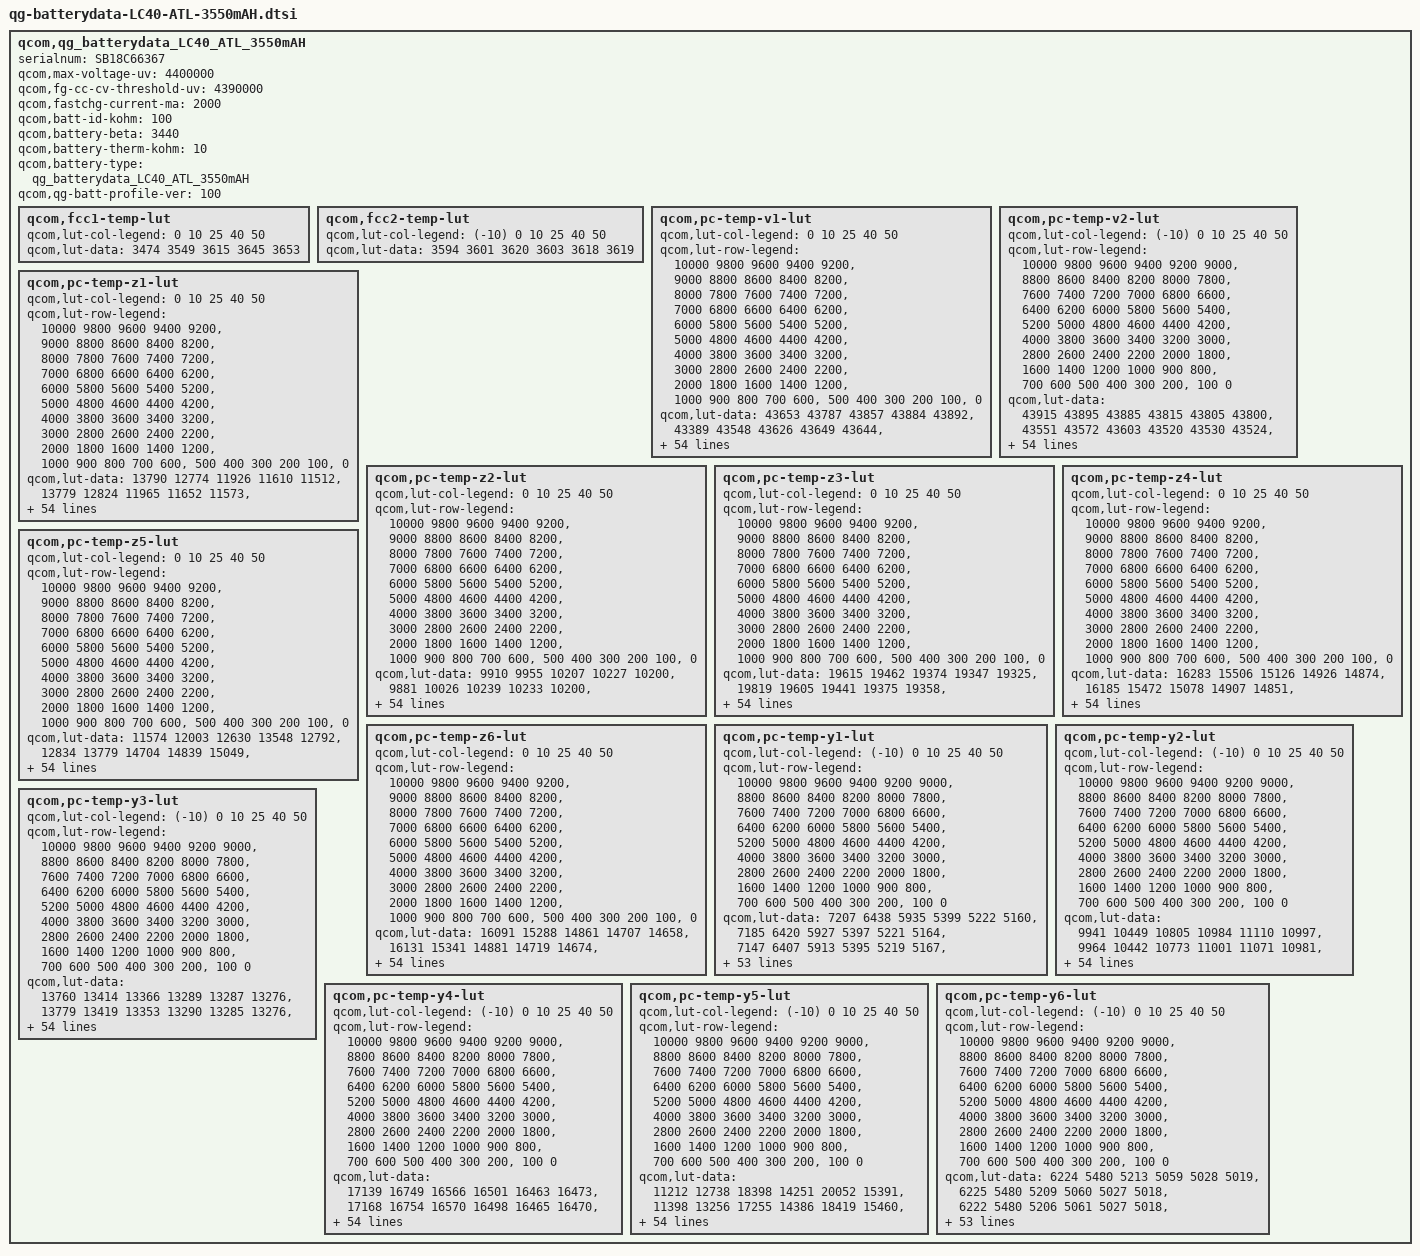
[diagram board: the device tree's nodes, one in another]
/* Copyright (c) 2014-2015, The Linux Foundation. All rights reserved.
 *
 * This program is free software; you can redistribute it and/or modify
 * it under the terms of the GNU General Public License version 2 and
 * only version 2 as published by the Free Software Foundation.
 *
 * This program is distributed in the hope that it will be useful,
 * but WITHOUT ANY WARRANTY; without even the implied warranty of
 * MERCHANTABILITY or FITNESS FOR A PARTICULAR PURPOSE.  See the
 * GNU General Public License for more details.
 */

qcom,qg_batterydata_LC40_ATL_3550mAH {
	/* qg_batterydata_LC40_ATL_3550mAH */
        serialnum = "SB18C66367";
   	qcom,max-voltage-uv = <4400000>;
    	qcom,fg-cc-cv-threshold-uv = <4390000>;
    	qcom,fastchg-current-ma = <2000>;
   	qcom,batt-id-kohm = <100>;
   	qcom,battery-beta = <3440>;
   	qcom,battery-therm-kohm = <10>;
   	qcom,battery-type = "qg_batterydata_LC40_ATL_3550mAH";
   	qcom,qg-batt-profile-ver = <100>;

	qcom,fcc1-temp-lut {
		qcom,lut-col-legend = <0 10 25 40 50>;
		qcom,lut-data = <3474 3549 3615 3645 3653>;
	};

	qcom,fcc2-temp-lut {
		qcom,lut-col-legend = <(-10) 0 10 25 40 50>;
		qcom,lut-data = <3594 3601 3620 3603 3618 3619>;
	};

	qcom,pc-temp-v1-lut {
		qcom,lut-col-legend = <0 10 25 40 50>;
		qcom,lut-row-legend = <10000 9800 9600 9400 9200>,
			<9000 8800 8600 8400 8200>,
			<8000 7800 7600 7400 7200>,
			<7000 6800 6600 6400 6200>,
			<6000 5800 5600 5400 5200>,
			<5000 4800 4600 4400 4200>,
			<4000 3800 3600 3400 3200>,
			<3000 2800 2600 2400 2200>,
			<2000 1800 1600 1400 1200>,
			<1000 900 800 700 600>,
			<500 400 300 200 100>,
			<0>;
		qcom,lut-data = <43653 43787 43857 43884 43892>,
			<43389 43548 43626 43649 43644>,
			<43118 43298 43383 43417 43420>,
			<42874 43047 43143 43187 43190>,
			<42643 42804 42903 42951 42961>,
			<42407 42563 42660 42714 42723>,
			<42171 42327 42419 42476 42488>,
			<41942 42092 42182 42238 42252>,
			<41717 41863 41949 42000 42016>,
			<41501 41636 41718 41767 41783>,
			<41303 41417 41490 41539 41555>,
			<41115 41216 41272 41317 41332>,
			<40908 41019 41069 41101 41111>,
			<40675 40808 40868 40892 40895>,
			<40445 40583 40650 40682 40687>,
			<40218 40368 40431 40475 40487>,
			<40006 40159 40229 40278 40295>,
			<39842 39972 40039 40093 40112>,
			<39708 39821 39870 39918 39936>,
			<39579 39687 39731 39767 39778>,
			<39451 39549 39586 39612 39618>,
			<39327 39410 39415 39393 39410>,
			<39200 39242 39228 39130 39161>,
			<39075 38991 39005 38940 38968>,
			<38953 38754 38759 38801 38822>,
			<38835 38610 38616 38682 38695>,
			<38716 38501 38540 38578 38580>,
			<38586 38425 38471 38483 38476>,
			<38463 38370 38395 38390 38382>,
			<38376 38322 38321 38303 38295>,
			<38310 38276 38254 38227 38216>,
			<38260 38234 38190 38157 38143>,
			<38221 38193 38137 38098 38079>,
			<38188 38154 38090 38046 38025>,
			<38160 38121 38049 37997 37972>,
			<38134 38091 38014 37948 37915>,
			<38104 38057 37977 37899 37855>,
			<38069 38017 37935 37849 37792>,
			<38025 37967 37886 37796 37724>,
			<37957 37894 37817 37726 37644>,
			<37865 37789 37712 37622 37548>,
			<37756 37674 37594 37505 37437>,
			<37621 37540 37459 37371 37300>,
			<37468 37391 37310 37225 37153>,
			<37321 37244 37163 37078 37011>,
			<37222 37154 37075 36993 36932>,
			<37192 37129 37050 36968 36910>,
			<37172 37107 37035 36952 36892>,
			<37150 37088 37017 36934 36873>,
			<37109 37050 36976 36882 36813>,
			<36909 36853 36770 36652 36557>,
			<36490 36430 36341 36209 36110>,
			<35919 35861 35774 35638 35537>,
			<35141 35084 35000 34857 34753>,
			<33932 33882 33805 33656 33550>,
			<30000 30000 30000 30000 30000>;
	};

	qcom,pc-temp-v2-lut {
		qcom,lut-col-legend = <(-10) 0 10 25 40 50>;
		qcom,lut-row-legend = <10000 9800 9600 9400 9200 9000>,
			<8800 8600 8400 8200 8000 7800>,
			<7600 7400 7200 7000 6800 6600>,
			<6400 6200 6000 5800 5600 5400>,
			<5200 5000 4800 4600 4400 4200>,
			<4000 3800 3600 3400 3200 3000>,
			<2800 2600 2400 2200 2000 1800>,
			<1600 1400 1200 1000 900 800>,
			<700 600 500 400 300 200>,
			<100 0>;
		qcom,lut-data = <43915 43895 43885 43815 43805 43800>,
			<43551 43572 43603 43520 43530 43524>,
			<43220 43274 43333 43244 43267 43262>,
			<42928 43002 43073 42988 43017 43014>,
			<42666 42754 42824 42749 42778 42779>,
			<42408 42508 42581 42511 42540 42543>,
			<42151 42263 42344 42273 42303 42306>,
			<41912 42025 42110 42037 42067 42070>,
			<41703 41796 41878 41805 41834 41837>,
			<41501 41573 41648 41576 41604 41606>,
			<41268 41355 41421 41350 41377 41381>,
			<41018 41143 41199 41129 41154 41161>,
			<40814 40942 40993 40919 40939 40944>,
			<40666 40760 40808 40723 40735 40734>,
			<40478 40546 40605 40523 40531 40528>,
			<40085 40234 40360 40303 40320 40325>,
			<39665 39906 40107 40089 40119 40131>,
			<39463 39665 39873 39915 39944 39954>,
			<39330 39464 39649 39759 39781 39786>,
			<39183 39289 39443 39583 39618 39622>,
			<39020 39137 39252 39386 39457 39463>,
			<38868 38991 39074 39183 39270 39278>,
			<38743 38843 38907 38966 39019 39029>,
			<38617 38701 38756 38767 38789 38800>,
			<38457 38568 38623 38620 38639 38649>,
			<38283 38445 38503 38498 38520 38527>,
			<38169 38335 38393 38391 38410 38416>,
			<38094 38236 38292 38294 38312 38316>,
			<38031 38140 38201 38206 38222 38224>,
			<37973 38037 38119 38124 38140 38138>,
			<37920 37951 38042 38050 38067 38062>,
			<37870 37897 37962 37982 37999 37993>,
			<37823 37856 37889 37921 37937 37930>,
			<37773 37818 37832 37863 37875 37869>,
			<37723 37783 37785 37809 37815 37810>,
			<37670 37746 37743 37756 37742 37731>,
			<37613 37707 37707 37702 37650 37616>,
			<37554 37664 37668 37644 37559 37505>,
			<37490 37614 37624 37575 37478 37416>,
			<37425 37557 37565 37500 37401 37335>,
			<37359 37485 37475 37423 37328 37262>,
			<37292 37390 37380 37333 37240 37175>,
			<37223 37275 37262 37210 37124 37058>,
			<37131 37136 37131 37086 37000 36933>,
			<37039 37006 36988 36940 36860 36802>,
			<36944 36916 36928 36897 36831 36772>,
			<36898 36885 36906 36884 36821 36761>,
			<36847 36848 36884 36872 36803 36748>,
			<36782 36792 36850 36845 36780 36721>,
			<36684 36706 36786 36781 36700 36624>,
			<36480 36508 36562 36544 36393 36291>,
			<36106 36096 36091 36068 35905 35797>,
			<35524 35486 35450 35451 35260 35147>,
			<34665 34639 34563 34627 34388 34262>,
			<33284 33307 33324 33395 33063 32929>,
			<28120 27938 28185 28434 27961 27898>;
	};

	qcom,pc-temp-z1-lut {
		qcom,lut-col-legend = <0 10 25 40 50>;
		qcom,lut-row-legend = <10000 9800 9600 9400 9200>,
			<9000 8800 8600 8400 8200>,
			<8000 7800 7600 7400 7200>,
			<7000 6800 6600 6400 6200>,
			<6000 5800 5600 5400 5200>,
			<5000 4800 4600 4400 4200>,
			<4000 3800 3600 3400 3200>,
			<3000 2800 2600 2400 2200>,
			<2000 1800 1600 1400 1200>,
			<1000 900 800 700 600>,
			<500 400 300 200 100>,
			<0>;
		qcom,lut-data = <13790 12774 11926 11610 11512>,
			<13779 12824 11965 11652 11573>,
			<13807 12796 11963 11657 11574>,
			<13790 12771 11956 11655 11576>,
			<13752 12753 11942 11651 11575>,
			<13735 12742 11933 11648 11574>,
			<13726 12723 11928 11647 11577>,
			<13719 12702 11926 11647 11578>,
			<13711 12688 11924 11647 11578>,
			<13702 12679 11924 11647 11578>,
			<13685 12674 11923 11648 11579>,
			<13657 12682 11923 11648 11579>,
			<13624 12693 11925 11649 11579>,
			<13572 12686 11926 11650 11580>,
			<13543 12657 11924 11650 11581>,
			<13554 12642 11921 11650 11581>,
			<13575 12638 11921 11650 11582>,
			<13586 12636 11922 11651 11585>,
			<13595 12648 11924 11652 11587>,
			<13598 12669 11927 11655 11588>,
			<13601 12676 11931 11657 11589>,
			<13606 12678 11936 11659 11589>,
			<13615 12680 11941 11661 11591>,
			<13627 12687 11946 11663 11593>,
			<13642 12696 11951 11666 11596>,
			<13662 12704 11956 11669 11600>,
			<13674 12713 11960 11673 11604>,
			<13661 12717 11965 11677 11608>,
			<13641 12721 11972 11681 11612>,
			<13640 12725 11979 11685 11615>,
			<13651 12735 11984 11689 11617>,
			<13662 12745 11988 11692 11620>,
			<13672 12750 11994 11695 11623>,
			<13682 12753 12001 11699 11627>,
			<13693 12759 12008 11703 11630>,
			<13704 12774 12015 11706 11632>,
			<13712 12787 12021 11708 11634>,
			<13718 12799 12027 11711 11636>,
			<13721 12811 12032 11714 11637>,
			<13725 12821 12039 11718 11640>,
			<13733 12833 12046 11721 11643>,
			<13753 12840 12052 11724 11645>,
			<13797 12845 12060 11728 11647>,
			<13802 12860 12064 11730 11649>,
			<13791 12880 12067 11732 11651>,
			<13785 12863 12078 11734 11653>,
			<13808 12861 12075 11734 11653>,
			<13783 12865 12078 11736 11653>,
			<13768 12873 12081 11736 11654>,
			<13771 12872 12083 11741 11657>,
			<13802 12893 12089 11745 11662>,
			<13841 12911 12100 11754 11669>,
			<13852 12943 12123 11766 11681>,
			<13889 12986 12154 11784 11696>,
			<13889 12986 12154 11784 11696>,
			<13889 12986 12154 11784 11696>;
	};

	qcom,pc-temp-z2-lut {
		qcom,lut-col-legend = <0 10 25 40 50>;
		qcom,lut-row-legend = <10000 9800 9600 9400 9200>,
			<9000 8800 8600 8400 8200>,
			<8000 7800 7600 7400 7200>,
			<7000 6800 6600 6400 6200>,
			<6000 5800 5600 5400 5200>,
			<5000 4800 4600 4400 4200>,
			<4000 3800 3600 3400 3200>,
			<3000 2800 2600 2400 2200>,
			<2000 1800 1600 1400 1200>,
			<1000 900 800 700 600>,
			<500 400 300 200 100>,
			<0>;
		qcom,lut-data = <9910 9955 10207 10227 10200>,
			<9881 10026 10239 10233 10200>,
			<9946 10052 10288 10250 10179>,
			<10003 10010 10275 10181 10147>,
			<10039 9981 10249 10307 10219>,
			<10038 9965 10214 10299 10304>,
			<10023 9962 10196 10248 10247>,
			<10018 9962 10191 10246 10234>,
			<10021 9962 10192 10283 10262>,
			<10026 9963 10197 10300 10278>,
			<10030 9964 10211 10294 10209>,
			<10033 9969 10224 10283 10129>,
			<10031 9977 10237 10245 10118>,
			<10012 9984 10245 10190 10115>,
			<9993 9990 10229 10169 10120>,
			<9986 9999 10202 10147 10133>,
			<9980 10017 10204 10141 10146>,
			<9973 10040 10228 10137 10156>,
			<9965 10075 10253 10136 10168>,
			<9957 10114 10276 10163 10188>,
			<9947 10133 10302 10221 10223>,
			<9938 10145 10341 10364 10334>,
			<9929 10152 10375 10592 10551>,
			<9921 10156 10364 10599 10587>,
			<9921 10160 10320 10352 10430>,
			<9928 10161 10295 10229 10342>,
			<9936 10162 10268 10287 10405>,
			<9947 10161 10256 10344 10472>,
			<9959 10157 10311 10350 10394>,
			<9965 10156 10375 10352 10219>,
			<9969 10158 10373 10332 10136>,
			<9973 10162 10361 10267 10088>,
			<9978 10168 10358 10243 10075>,
			<9984 10178 10359 10249 10092>,
			<9988 10184 10360 10257 10121>,
			<9994 10190 10365 10278 10175>,
			<10001 10197 10375 10317 10248>,
			<10014 10205 10395 10364 10311>,
			<10027 10215 10427 10420 10368>,
			<10037 10227 10455 10453 10383>,
			<10047 10240 10485 10508 10382>,
			<10061 10245 10495 10527 10381>,
			<10080 10244 10493 10464 10383>,
			<10103 10249 10492 10430 10377>,
			<10177 10283 10499 10453 10355>,
			<10409 10446 10532 10403 10335>,
			<10481 10484 10524 10395 10337>,
			<10431 10497 10499 10394 10336>,
			<10411 10571 10497 10428 10376>,
			<10418 10628 10540 10487 10433>,
			<10472 10587 10624 10413 10271>,
			<10319 10549 10586 10263 10109>,
			<10145 10508 10524 10199 10054>,
			<9956 10341 10465 10125 9980>,
			<9956 10341 10465 10125 9980>,
			<9956 10341 10465 10125 9980>;
	};

	qcom,pc-temp-z3-lut {
		qcom,lut-col-legend = <0 10 25 40 50>;
		qcom,lut-row-legend = <10000 9800 9600 9400 9200>,
			<9000 8800 8600 8400 8200>,
			<8000 7800 7600 7400 7200>,
			<7000 6800 6600 6400 6200>,
			<6000 5800 5600 5400 5200>,
			<5000 4800 4600 4400 4200>,
			<4000 3800 3600 3400 3200>,
			<3000 2800 2600 2400 2200>,
			<2000 1800 1600 1400 1200>,
			<1000 900 800 700 600>,
			<500 400 300 200 100>,
			<0>;
		qcom,lut-data = <19615 19462 19374 19347 19325>,
			<19819 19605 19441 19375 19358>,
			<19970 19632 19460 19388 19361>,
			<19893 19737 19455 19386 19374>,
			<19775 19743 19524 19418 19384>,
			<19734 19744 19526 19445 19427>,
			<19707 19742 19527 19444 19428>,
			<19698 19734 19517 19443 19428>,
			<19702 19726 19497 19437 19423>,
			<19706 19713 19486 19430 19416>,
			<19710 19697 19480 19419 19404>,
			<19715 19675 19472 19408 19393>,
			<19725 19650 19458 19402 19389>,
			<19744 19633 19449 19397 19386>,
			<19759 19621 19453 19392 19382>,
			<19761 19607 19458 19386 19375>,
			<19759 19591 19457 19381 19370>,
			<19760 19575 19447 19377 19366>,
			<19761 19556 19439 19373 19362>,
			<19762 19540 19431 19366 19356>,
			<19764 19539 19427 19361 19350>,
			<19765 19548 19436 19370 19355>,
			<19774 19561 19448 19395 19370>,
			<19786 19591 19449 19395 19370>,
			<19790 19615 19446 19359 19338>,
			<19797 19614 19439 19341 19321>,
			<19807 19611 19422 19348 19363>,
			<19819 19607 19412 19360 19407>,
			<19831 19601 19416 19383 19407>,
			<19831 19595 19423 19412 19402>,
			<19824 19589 19437 19414 19398>,
			<19814 19583 19457 19409 19391>,
			<19802 19579 19461 19403 19383>,
			<19786 19577 19458 19395 19372>,
			<19771 19573 19454 19387 19362>,
			<19755 19567 19447 19381 19356>,
			<19739 19563 19439 19376 19352>,
			<19722 19561 19434 19372 19353>,
			<19710 19560 19430 19368 19357>,
			<19707 19557 19426 19367 19358>,
			<19704 19551 19421 19367 19357>,
			<19695 19547 19419 19368 19356>,
			<19675 19544 19420 19367 19359>,
			<19661 19538 19419 19366 19362>,
			<19630 19524 19415 19368 19364>,
			<19522 19462 19391 19352 19347>,
			<19489 19436 19387 19349 19335>,
			<19387 19430 19370 19341 19333>,
			<19355 19409 19364 19338 19324>,
			<19347 19403 19360 19334 19321>,
			<19403 19414 19351 19345 19350>,
			<19374 19412 19347 19358 19359>,
			<19374 19393 19343 19357 19361>,
			<19371 19361 19343 19361 19366>,
			<19371 19361 19343 19361 19366>,
			<19371 19361 19343 19361 19366>;
	};

	qcom,pc-temp-z4-lut {
		qcom,lut-col-legend = <0 10 25 40 50>;
		qcom,lut-row-legend = <10000 9800 9600 9400 9200>,
			<9000 8800 8600 8400 8200>,
			<8000 7800 7600 7400 7200>,
			<7000 6800 6600 6400 6200>,
			<6000 5800 5600 5400 5200>,
			<5000 4800 4600 4400 4200>,
			<4000 3800 3600 3400 3200>,
			<3000 2800 2600 2400 2200>,
			<2000 1800 1600 1400 1200>,
			<1000 900 800 700 600>,
			<500 400 300 200 100>,
			<0>;
		qcom,lut-data = <16283 15506 15126 14926 14874>,
			<16185 15472 15078 14907 14851>,
			<16901 15212 14941 14837 14800>,
			<16791 15504 14872 14792 14762>,
			<16501 15405 15024 14826 14760>,
			<16279 15225 14972 14865 14825>,
			<16084 15118 14905 14825 14789>,
			<15916 15037 14868 14798 14767>,
			<15769 14976 14839 14777 14754>,
			<15643 14925 14822 14766 14748>,
			<15538 14890 14809 14762 14746>,
			<15447 14868 14798 14759 14744>,
			<15364 14853 14790 14752 14739>,
			<15289 14849 14782 14744 14731>,
			<15223 14847 14771 14738 14723>,
			<15167 14844 14758 14733 14717>,
			<15115 14835 14747 14726 14710>,
			<15062 14823 14738 14715 14701>,
			<15009 14808 14728 14705 14693>,
			<14967 14791 14715 14698 14687>,
			<14934 14775 14709 14694 14682>,
			<14906 14757 14716 14720 14704>,
			<14882 14753 14735 14795 14776>,
			<14859 14825 14792 14849 14830>,
			<14848 14900 14901 14893 14872>,
			<14837 14916 14929 14908 14888>,
			<14832 14925 14913 14886 14829>,
			<14843 14922 14892 14849 14758>,
			<14862 14897 14868 14803 14738>,
			<14867 14870 14839 14753 14726>,
			<14867 14849 14806 14733 14717>,
			<14865 14828 14771 14722 14710>,
			<14856 14809 14751 14715 14704>,
			<14844 14792 14739 14708 14698>,
			<14836 14778 14732 14705 14695>,
			<14830 14765 14727 14709 14699>,
			<14823 14755 14725 14715 14705>,
			<14818 14747 14726 14718 14711>,
			<14812 14742 14727 14720 14718>,
			<14804 14745 14731 14725 14721>,
			<14796 14752 14741 14733 14723>,
			<14798 14753 14745 14736 14724>,
			<14806 14749 14737 14734 14721>,
			<14801 14745 14733 14731 14720>,
			<14785 14741 14730 14730 14719>,
			<14785 14721 14696 14698 14692>,
			<14813 14740 14690 14689 14690>,
			<14919 14737 14688 14675 14669>,
			<14948 14748 14677 14652 14652>,
			<14945 14747 14677 14652 14649>,
			<14892 14753 14713 14674 14658>,
			<14950 14772 14736 14679 14666>,
			<14973 14806 14745 14683 14664>,
			<15004 14854 14752 14681 14662>,
			<15004 14854 14752 14681 14662>,
			<15004 14854 14752 14681 14662>;
	};

	qcom,pc-temp-z5-lut {
		qcom,lut-col-legend = <0 10 25 40 50>;
		qcom,lut-row-legend = <10000 9800 9600 9400 9200>,
			<9000 8800 8600 8400 8200>,
			<8000 7800 7600 7400 7200>,
			<7000 6800 6600 6400 6200>,
			<6000 5800 5600 5400 5200>,
			<5000 4800 4600 4400 4200>,
			<4000 3800 3600 3400 3200>,
			<3000 2800 2600 2400 2200>,
			<2000 1800 1600 1400 1200>,
			<1000 900 800 700 600>,
			<500 400 300 200 100>,
			<0>;
		qcom,lut-data = <11574 12003 12630 13548 12792>,
			<12834 13779 14704 14839 15049>,
			<12716 15308 16751 16693 15935>,
			<12486 14314 17469 17345 18361>,
			<12423 14524 15825 17935 19105>,
			<12475 14993 16214 17319 18888>,
			<12656 15447 16688 17644 19659>,
			<12814 15985 16858 18089 20269>,
			<12956 16460 16922 18797 20780>,
			<13096 17071 16984 19063 20977>,
			<13210 17446 17258 18462 19996>,
			<13321 17448 17327 17914 18924>,
			<13470 17420 17093 17970 19105>,
			<13674 17367 16917 18076 19567>,
			<13855 17264 17265 18000 19597>,
			<13987 17119 18029 17702 19359>,
			<14150 16844 18664 17663 19299>,
			<14426 16611 19278 18318 19895>,
			<14854 16706 20065 19045 20583>,
			<15348 17126 21109 19409 20894>,
			<15965 17931 22631 19860 21218>,
			<16681 20165 26899 24633 23291>,
			<17743 23965 31427 34776 27962>,
			<19273 35887 31051 34879 27977>,
			<20796 45773 28354 22312 19055>,
			<23046 43500 25412 15498 13977>,
			<26053 37523 20638 14938 15849>,
			<31332 33285 17949 14712 18305>,
			<36534 29955 17624 16088 19346>,
			<36898 27656 17525 19053 20143>,
			<35332 25969 18803 20929 21060>,
			<33643 24994 22212 22334 22254>,
			<31391 25030 24985 23503 22650>,
			<28873 25247 27477 24511 22513>,
			<26645 25338 28852 25342 22404>,
			<24553 25397 29317 26173 22880>,
			<23150 25516 29361 26769 23830>,
			<22058 26642 28949 26412 24784>,
			<21577 27889 28222 25216 25796>,
			<22244 27773 26990 24133 25610>,
			<23213 27170 24817 22451 22737>,
			<22783 26566 23881 21406 21142>,
			<21081 25800 24122 20956 21531>,
			<21340 25325 23974 20518 21674>,
			<21563 24229 22999 20034 21034>,
			<17857 21102 22217 19527 19333>,
			<15524 16939 21456 19339 17278>,
			<12642 16476 18274 18814 18322>,
			<11999 15197 18036 21032 19389>,
			<11977 15046 17806 20781 20070>,
			<13361 15443 15490 17858 21169>,
			<12350 14816 14163 17229 19082>,
			<12067 13503 13589 16231 18563>,
			<11749 12394 13253 16162 18344>,
			<11749 12394 13253 16162 18344>,
			<11749 12394 13253 16162 18344>;
	};

	qcom,pc-temp-z6-lut {
		qcom,lut-col-legend = <0 10 25 40 50>;
		qcom,lut-row-legend = <10000 9800 9600 9400 9200>,
			<9000 8800 8600 8400 8200>,
			<8000 7800 7600 7400 7200>,
			<7000 6800 6600 6400 6200>,
			<6000 5800 5600 5400 5200>,
			<5000 4800 4600 4400 4200>,
			<4000 3800 3600 3400 3200>,
			<3000 2800 2600 2400 2200>,
			<2000 1800 1600 1400 1200>,
			<1000 900 800 700 600>,
			<500 400 300 200 100>,
			<0>;
		qcom,lut-data = <16091 15288 14861 14707 14658>,
			<16131 15341 14881 14719 14674>,
			<16492 15235 14834 14697 14655>,
			<16395 15405 14799 14676 14645>,
			<16187 15360 14900 14709 14650>,
			<16051 15276 14879 14741 14703>,
			<15943 15221 14850 14724 14690>,
			<15856 15178 14826 14711 14679>,
			<15786 15142 14804 14699 14672>,
			<15727 15110 14790 14690 14664>,
			<15679 15085 14781 14682 14657>,
			<15638 15065 14772 14675 14650>,
			<15598 15048 14761 14668 14645>,
			<15559 15033 14753 14662 14640>,
			<15525 15019 14749 14656 14634>,
			<15496 15006 14746 14650 14628>,
			<15471 14994 14740 14644 14622>,
			<15451 14981 14731 14638 14616>,
			<15434 14965 14722 14631 14610>,
			<15421 14950 14712 14624 14603>,
			<15410 14947 14707 14619 14598>,
			<15403 14947 14714 14638 14612>,
			<15401 14950 14730 14686 14654>,
			<15400 14997 14759 14701 14670>,
			<15400 15044 14803 14703 14674>,
			<15403 15052 14813 14704 14675>,
			<15408 15055 14798 14698 14672>,
			<15421 15054 14784 14690 14666>,
			<15436 15042 14776 14684 14660>,
			<15439 15030 14770 14678 14653>,
			<15438 15019 14764 14672 14646>,
			<15436 15008 14760 14665 14639>,
			<15427 15000 14754 14658 14633>,
			<15417 14993 14749 14651 14624>,
			<15409 14987 14744 14646 14618>,
			<15402 14981 14738 14644 14617>,
			<15395 14978 14734 14643 14616>,
			<15388 14977 14732 14643 14618>,
			<15384 14976 14731 14642 14622>,
			<15385 14978 14732 14642 14624>,
			<15387 14981 14735 14647 14625>,
			<15386 14983 14737 14649 14625>,
			<15382 14982 14735 14647 14626>,
			<15378 14981 14733 14647 14627>,
			<15362 14975 14731 14647 14629>,
			<15315 14940 14706 14625 14608>,
			<15308 14935 14701 14620 14600>,
			<15299 14930 14691 14610 14591>,
			<15296 14926 14684 14598 14578>,
			<15298 14925 14683 14596 14575>,
			<15312 14936 14695 14613 14596>,
			<15332 14952 14706 14625 14607>,
			<15360 14968 14713 14629 14611>,
			<15400 14990 14723 14635 14617>,
			<15400 14990 14723 14635 14617>,
			<15400 14990 14723 14635 14617>;
	};

	qcom,pc-temp-y1-lut {
		qcom,lut-col-legend = <(-10) 0 10 25 40 50>;
		qcom,lut-row-legend = <10000 9800 9600 9400 9200 9000>,
			<8800 8600 8400 8200 8000 7800>,
			<7600 7400 7200 7000 6800 6600>,
			<6400 6200 6000 5800 5600 5400>,
			<5200 5000 4800 4600 4400 4200>,
			<4000 3800 3600 3400 3200 3000>,
			<2800 2600 2400 2200 2000 1800>,
			<1600 1400 1200 1000 900 800>,
			<700 600 500 400 300 200>,
			<100 0>;
		qcom,lut-data = <7207 6438 5935 5399 5222 5160>,
			<7185 6420 5927 5397 5221 5164>,
			<7147 6407 5913 5395 5219 5167>,
			<7107 6398 5898 5393 5218 5170>,
			<7077 6394 5886 5390 5217 5171>,
			<7068 6394 5881 5388 5216 5171>,
			<7065 6401 5879 5386 5215 5170>,
			<7064 6405 5876 5384 5215 5169>,
			<7087 6389 5872 5382 5214 5170>,
			<7117 6371 5867 5380 5213 5170>,
			<7118 6368 5859 5379 5212 5170>,
			<7109 6367 5847 5378 5212 5170>,
			<7099 6367 5843 5378 5212 5170>,
			<7085 6372 5839 5377 5212 5169>,
			<7078 6376 5837 5377 5213 5169>,
			<7102 6385 5836 5379 5214 5170>,
			<7131 6394 5836 5381 5214 5170>,
			<7124 6395 5839 5382 5215 5171>,
			<7099 6395 5844 5384 5216 5171>,
			<7085 6394 5847 5386 5216 5172>,
			<7078 6392 5849 5387 5216 5174>,
			<7075 6391 5849 5389 5217 5175>,
			<7076 6394 5843 5392 5217 5175>,
			<7076 6400 5839 5396 5219 5176>,
			<7075 6409 5845 5399 5220 5177>,
			<7073 6419 5855 5402 5222 5178>,
			<7074 6420 5860 5405 5224 5179>,
			<7086 6416 5868 5410 5226 5182>,
			<7092 6412 5870 5415 5228 5184>,
			<7077 6405 5873 5421 5231 5186>,
			<7060 6401 5876 5426 5235 5188>,
			<7059 6401 5882 5431 5238 5190>,
			<7066 6403 5888 5436 5242 5193>,
			<7076 6409 5892 5441 5245 5194>,
			<7090 6423 5895 5446 5247 5196>,
			<7094 6433 5899 5450 5250 5198>,
			<7075 6433 5906 5454 5252 5200>,
			<7056 6431 5912 5458 5254 5202>,
			<7052 6427 5916 5462 5255 5204>,
			<7046 6424 5922 5464 5256 5205>,
			<7044 6428 5938 5466 5258 5207>,
			<7064 6461 5931 5471 5260 5208>,
			<7087 6452 5943 5476 5263 5210>,
			<7093 6456 5950 5481 5265 5213>,
			<7074 6448 5974 5488 5267 5215>,
			<7090 6448 5976 5497 5272 5217>,
			<7069 6443 5985 5497 5273 5218>,
			<7077 6432 5992 5506 5273 5218>,
			<7121 6440 6003 5507 5273 5218>,
			<7082 6444 6003 5509 5274 5217>,
			<7096 6458 6009 5515 5276 5222>,
			<7093 6466 6035 5527 5282 5227>,
			<7130 6516 6057 5552 5292 5235>,
			<7250 6517 6085 5578 5306 5245>,
			<7250 6517 6085 5578 5306 5245>,
			<7250 6517 6085 5578 5306 5245>;
	};

	qcom,pc-temp-y2-lut {
		qcom,lut-col-legend = <(-10) 0 10 25 40 50>;
		qcom,lut-row-legend = <10000 9800 9600 9400 9200 9000>,
			<8800 8600 8400 8200 8000 7800>,
			<7600 7400 7200 7000 6800 6600>,
			<6400 6200 6000 5800 5600 5400>,
			<5200 5000 4800 4600 4400 4200>,
			<4000 3800 3600 3400 3200 3000>,
			<2800 2600 2400 2200 2000 1800>,
			<1600 1400 1200 1000 900 800>,
			<700 600 500 400 300 200>,
			<100 0>;
		qcom,lut-data = <9941 10449 10805 10984 11110 10997>,
			<9964 10442 10773 11001 11071 10981>,
			<9995 10434 10742 11004 10993 10961>,
			<10026 10426 10713 10997 10908 10938>,
			<10047 10422 10687 10981 10845 10911>,
			<10051 10421 10664 10958 10829 10880>,
			<10046 10422 10640 10911 10827 10845>,
			<10043 10425 10628 10876 10826 10811>,
			<10078 10441 10628 10862 10833 10776>,
			<10154 10460 10629 10853 10840 10747>,
			<10283 10456 10637 10852 10836 10731>,
			<10468 10443 10654 10848 10827 10719>,
			<10508 10460 10662 10841 10808 10715>,
			<10446 10607 10664 10831 10762 10721>,
			<10406 10694 10670 10827 10741 10724>,
			<10436 10687 10753 10879 10815 10726>,
			<10493 10679 10832 10957 10913 10733>,
			<10574 10681 10827 11004 10957 10765>,
			<10679 10689 10813 11045 10992 10835>,
			<10722 10701 10815 11080 11089 10945>,
			<10739 10728 10839 11121 11299 11128>,
			<10745 10755 10866 11137 11371 11191>,
			<10722 10779 10897 11101 11191 11082>,
			<10667 10804 10926 11065 11034 10983>,
			<10391 10832 10947 11076 11026 10984>,
			<9855 10859 10964 11106 11025 11006>,
			<9707 10864 10977 11136 11040 11035>,
			<9689 10864 10989 11169 11093 11077>,
			<9680 10865 11001 11194 11138 11111>,
			<9676 10876 11016 11210 11175 11144>,
			<9673 10887 11025 11225 11202 11176>,
			<9670 10879 11025 11249 11227 11208>,
			<9668 10860 11025 11272 11246 11238>,
			<9666 10844 11023 11267 11262 11256>,
			<9664 10830 11016 11235 11298 11269>,
			<9662 10815 11008 11217 11293 11254>,
			<9661 10796 10992 11210 11211 11170>,
			<9659 10773 10974 11202 11137 11108>,
			<9658 10746 10954 11172 11097 11092>,
			<9658 10712 10930 11141 11079 11082>,
			<9657 10664 10897 11131 11097 11077>,
			<9656 10601 10877 11140 11074 11061>,
			<9657 10582 10871 11106 11117 11045>,
			<9656 10477 10846 11110 11113 11038>,
			<9655 9738 10794 11093 11035 10964>,
			<9654 9678 10696 11016 10931 10815>,
			<9654 9671 10646 11002 10894 10760>,
			<9654 9666 10594 10990 10911 10781>,
			<9654 9662 10566 10985 10962 10852>,
			<9653 9659 10527 10990 10954 10784>,
			<9653 9657 10457 10979 10853 10750>,
			<9652 9654 10352 10920 10781 10658>,
			<9651 9652 10182 10826 10733 10565>,
			<9649 9651 9786 10759 10655 10484>,
			<9649 9651 9786 10759 10655 10484>,
			<9649 9651 9786 10759 10655 10484>;
	};

	qcom,pc-temp-y3-lut {
		qcom,lut-col-legend = <(-10) 0 10 25 40 50>;
		qcom,lut-row-legend = <10000 9800 9600 9400 9200 9000>,
			<8800 8600 8400 8200 8000 7800>,
			<7600 7400 7200 7000 6800 6600>,
			<6400 6200 6000 5800 5600 5400>,
			<5200 5000 4800 4600 4400 4200>,
			<4000 3800 3600 3400 3200 3000>,
			<2800 2600 2400 2200 2000 1800>,
			<1600 1400 1200 1000 900 800>,
			<700 600 500 400 300 200>,
			<100 0>;
		qcom,lut-data = <13760 13414 13366 13289 13287 13276>,
			<13779 13419 13353 13290 13285 13276>,
			<13786 13428 13346 13291 13283 13277>,
			<13784 13437 13342 13292 13283 13278>,
			<13778 13445 13341 13294 13283 13279>,
			<13766 13446 13342 13295 13284 13280>,
			<13741 13446 13348 13297 13287 13281>,
			<13727 13446 13352 13298 13289 13281>,
			<13761 13446 13353 13299 13291 13282>,
			<13805 13446 13354 13299 13292 13283>,
			<13752 13450 13354 13302 13293 13285>,
			<13598 13459 13355 13308 13294 13289>,
			<13555 13461 13358 13310 13294 13291>,
			<13570 13456 13366 13310 13294 13291>,
			<13579 13449 13369 13310 13294 13292>,
			<13569 13437 13368 13310 13298 13292>,
			<13549 13423 13366 13310 13301 13291>,
			<13526 13413 13361 13310 13301 13292>,
			<13498 13404 13353 13310 13299 13294>,
			<13472 13398 13347 13309 13299 13295>,
			<13444 13393 13343 13309 13299 13296>,
			<13433 13390 13338 13308 13299 13296>,
			<13436 13387 13332 13304 13290 13287>,
			<13439 13384 13328 13299 13282 13280>,
			<13432 13379 13328 13295 13282 13280>,
			<13415 13372 13327 13293 13282 13280>,
			<13406 13370 13327 13293 13282 13280>,
			<13404 13369 13326 13294 13282 13280>,
			<13405 13368 13327 13294 13282 13279>,
			<13415 13359 13328 13295 13282 13278>,
			<13430 13352 13329 13295 13282 13277>,
			<13442 13354 13328 13296 13282 13278>,
			<13459 13358 13325 13297 13282 13278>,
			<13480 13362 13325 13298 13283 13279>,
			<13508 13365 13326 13298 13283 13281>,
			<13540 13369 13327 13298 13283 13281>,
			<13580 13371 13329 13298 13282 13279>,
			<13625 13374 13331 13299 13281 13278>,
			<13676 13377 13335 13298 13281 13278>,
			<13733 13379 13336 13297 13281 13279>,
			<13799 13383 13333 13297 13282 13280>,
			<13844 13383 13332 13297 13282 13281>,
			<13763 13374 13324 13292 13282 13280>,
			<13862 13370 13325 13292 13282 13280>,
			<14010 13390 13323 13293 13278 13277>,
			<14157 13422 13331 13293 13285 13282>,
			<14241 13459 13336 13293 13289 13285>,
			<14328 13501 13342 13302 13291 13291>,
			<14420 13571 13352 13304 13298 13294>,
			<14532 13672 13367 13312 13298 13292>,
			<14665 13799 13370 13308 13290 13288>,
			<14891 14026 13378 13305 13292 13290>,
			<15404 14401 13401 13314 13296 13294>,
			<17051 14801 13460 13329 13305 13300>,
			<17051 14801 13460 13329 13305 13300>,
			<17051 14801 13460 13329 13305 13300>;
	};

	qcom,pc-temp-y4-lut {
		qcom,lut-col-legend = <(-10) 0 10 25 40 50>;
		qcom,lut-row-legend = <10000 9800 9600 9400 9200 9000>,
			<8800 8600 8400 8200 8000 7800>,
			<7600 7400 7200 7000 6800 6600>,
			<6400 6200 6000 5800 5600 5400>,
			<5200 5000 4800 4600 4400 4200>,
			<4000 3800 3600 3400 3200 3000>,
			<2800 2600 2400 2200 2000 1800>,
			<1600 1400 1200 1000 900 800>,
			<700 600 500 400 300 200>,
			<100 0>;
		qcom,lut-data = <17139 16749 16566 16501 16463 16473>,
			<17168 16754 16570 16498 16465 16470>,
			<17197 16758 16576 16497 16466 16467>,
			<17224 16764 16582 16498 16468 16464>,
			<17249 16770 16587 16499 16469 16463>,
			<17273 16777 16589 16501 16469 16463>,
			<17300 16784 16590 16504 16468 16464>,
			<17313 16793 16591 16509 16468 16466>,
			<17222 16815 16601 16517 16470 16469>,
			<17104 16836 16618 16525 16474 16472>,
			<17196 16837 16635 16529 16479 16473>,
			<17473 16836 16655 16532 16485 16473>,
			<17552 16851 16677 16538 16494 16475>,
			<17543 16964 16703 16557 16507 16481>,
			<17523 17030 16726 16578 16516 16488>,
			<17245 16949 16749 16597 16519 16496>,
			<16919 16829 16763 16619 16523 16505>,
			<16915 16758 16740 16651 16538 16516>,
			<16960 16704 16684 16685 16565 16529>,
			<16970 16692 16636 16688 16595 16550>,
			<16958 16691 16591 16661 16631 16585>,
			<16939 16689 16567 16623 16639 16595>,
			<16893 16679 16557 16554 16562 16538>,
			<16847 16668 16551 16499 16490 16484>,
			<16836 16662 16548 16494 16479 16473>,
			<16830 16659 16547 16491 16474 16467>,
			<16830 16652 16547 16492 16475 16468>,
			<16836 16639 16550 16496 16479 16472>,
			<16840 16627 16552 16501 16486 16477>,
			<16841 16612 16556 16507 16495 16487>,
			<16842 16602 16559 16515 16507 16499>,
			<16843 16604 16555 16523 16520 16510>,
			<16845 16610 16551 16531 16533 16521>,
			<16847 16618 16551 16537 16538 16532>,
			<16849 16630 16553 16541 16541 16541>,
			<16850 16644 16557 16542 16539 16539>,
			<16852 16660 16569 16536 16511 16506>,
			<16853 16675 16580 16526 16489 16481>,
			<16855 16688 16588 16511 16480 16473>,
			<16858 16695 16590 16501 16478 16471>,
			<16861 16694 16580 16502 16486 16479>,
			<16860 16681 16568 16501 16486 16481>,
			<16818 16627 16540 16487 16471 16466>,
			<16826 16626 16541 16492 16477 16469>,
			<16817 16681 16543 16472 16454 16446>,
			<16852 16723 16556 16489 16469 16463>,
			<16872 16743 16576 16508 16480 16481>,
			<16899 16780 16605 16518 16503 16507>,
			<16932 16831 16644 16550 16537 16546>,
			<16962 16900 16700 16572 16551 16549>,
			<16963 16930 16705 16545 16488 16474>,
			<16931 16915 16672 16523 16479 16471>,
			<16946 16925 16721 16536 16485 16478>,
			<17319 16954 16832 16587 16528 16516>,
			<17319 16954 16832 16587 16528 16516>,
			<17319 16954 16832 16587 16528 16516>;
	};

	qcom,pc-temp-y5-lut {
		qcom,lut-col-legend = <(-10) 0 10 25 40 50>;
		qcom,lut-row-legend = <10000 9800 9600 9400 9200 9000>,
			<8800 8600 8400 8200 8000 7800>,
			<7600 7400 7200 7000 6800 6600>,
			<6400 6200 6000 5800 5600 5400>,
			<5200 5000 4800 4600 4400 4200>,
			<4000 3800 3600 3400 3200 3000>,
			<2800 2600 2400 2200 2000 1800>,
			<1600 1400 1200 1000 900 800>,
			<700 600 500 400 300 200>,
			<100 0>;
		qcom,lut-data = <11212 12738 18398 14251 20052 15391>,
			<11398 13256 17255 14386 18419 15460>,
			<11782 13811 16037 14427 17152 15464>,
			<12211 14300 14972 14397 16270 15420>,
			<12531 14618 14286 14322 15794 15343>,
			<12611 14666 14197 14219 15796 15244>,
			<12615 14516 14536 14055 16420 15103>,
			<12630 14414 14740 13845 16744 14931>,
			<14903 14441 14351 13484 16503 14642>,
			<17858 14518 13874 13170 16124 14404>,
			<16692 14874 13796 13334 15693 14854>,
			<12873 15620 13765 13805 15167 15919>,
			<12252 15770 13812 13837 14582 16079>,
			<15958 15452 14201 13184 13862 15542>,
			<18289 15285 14821 12732 13579 14959>,
			<17759 17035 16248 12704 13961 14360>,
			<16873 19044 17869 12807 14341 13952>,
			<16119 18488 19068 13164 14088 13904>,
			<15373 16928 20013 13989 13580 13884>,
			<15198 16531 20026 15445 13873 14017>,
			<15198 16644 19413 18465 15578 14713>,
			<15235 16814 18652 19866 16542 15462>,
			<16988 17165 17448 19644 16805 16258>,
			<18971 17460 16665 19242 16926 16878>,
			<17313 17308 16675 18233 16947 17325>,
			<13141 16967 16720 16707 16953 17727>,
			<11975 17204 16808 16427 16802 17560>,
			<11851 18727 17004 16893 16262 16690>,
			<11822 19387 17338 17145 15937 15837>,
			<11876 17338 18490 17273 15772 14905>,
			<11960 15373 19221 17464 15700 14417>,
			<12061 15626 18935 17896 15835 14523>,
			<12204 16311 18499 18608 16116 14773>,
			<12288 16814 18420 19105 16667 15435>,
			<12363 17240 18585 19562 17637 16709>,
			<12388 17482 18704 20000 17871 17197>,
			<12379 17625 18805 20503 17722 17292>,
			<12366 17750 18983 20789 17586 17419>,
			<12280 17887 19730 20299 17418 17845>,
			<12173 17989 19928 19377 17164 17999>,
			<12144 18049 18082 18310 16681 17500>,
			<12168 17639 17749 18101 16603 17680>,
			<12138 17076 16785 16536 17045 17695>,
			<11978 15186 16405 16434 16710 17525>,
			<12229 12784 15094 17430 16137 17411>,
			<12194 12289 15346 15338 15812 15013>,
			<12349 12535 15018 14421 15831 14992>,
			<12467 12575 14701 15621 15117 15763>,
			<12687 12589 14626 14840 15919 15492>,
			<13078 12894 15352 15549 15655 14676>,
			<13118 12933 15051 15665 15448 16810>,
			<12852 12785 15212 15541 16771 17104>,
			<12259 12529 14409 17143 17939 18569>,
			<10878 12345 13064 20427 22076 21886>,
			<10878 12345 13064 20427 22076 21886>,
			<10878 12345 13064 20427 22076 21886>;
	};

	qcom,pc-temp-y6-lut {
		qcom,lut-col-legend = <(-10) 0 10 25 40 50>;
		qcom,lut-row-legend = <10000 9800 9600 9400 9200 9000>,
			<8800 8600 8400 8200 8000 7800>,
			<7600 7400 7200 7000 6800 6600>,
			<6400 6200 6000 5800 5600 5400>,
			<5200 5000 4800 4600 4400 4200>,
			<4000 3800 3600 3400 3200 3000>,
			<2800 2600 2400 2200 2000 1800>,
			<1600 1400 1200 1000 900 800>,
			<700 600 500 400 300 200>,
			<100 0>;
		qcom,lut-data = <6224 5480 5213 5059 5028 5019>,
			<6225 5480 5209 5060 5027 5018>,
			<6222 5480 5206 5061 5027 5018>,
			<6215 5480 5203 5062 5028 5019>,
			<6206 5480 5201 5063 5028 5019>,
			<6194 5479 5201 5064 5029 5020>,
			<6177 5475 5201 5066 5031 5021>,
			<6164 5472 5203 5068 5033 5022>,
			<6159 5473 5205 5071 5034 5024>,
			<6155 5475 5208 5073 5036 5025>,
			<6141 5476 5212 5077 5038 5027>,
			<6119 5476 5216 5081 5041 5030>,
			<6115 5481 5223 5085 5043 5032>,
			<6128 5504 5234 5090 5047 5034>,
			<6135 5517 5242 5096 5050 5036>,
			<6060 5488 5247 5101 5053 5039>,
			<5967 5445 5249 5108 5057 5041>,
			<5962 5420 5240 5117 5062 5045>,
			<5966 5401 5218 5126 5068 5050>,
			<5965 5393 5201 5127 5076 5057>,
			<5953 5390 5184 5118 5086 5067>,
			<5945 5388 5174 5107 5087 5070>,
			<5951 5385 5167 5084 5059 5046>,
			<5957 5383 5164 5065 5033 5025>,
			<5952 5382 5163 5061 5029 5022>,
			<5940 5382 5163 5059 5028 5020>,
			<5940 5382 5163 5059 5028 5020>,
			<5961 5384 5165 5062 5029 5022>,
			<5987 5385 5167 5064 5031 5023>,
			<6011 5385 5172 5067 5034 5025>,
			<6037 5386 5175 5070 5038 5028>,
			<6064 5393 5175 5073 5042 5032>,
			<6091 5410 5174 5077 5046 5036>,
			<6123 5426 5175 5080 5049 5039>,
			<6160 5444 5179 5082 5050 5043>,
			<6201 5464 5184 5082 5049 5043>,
			<6247 5487 5191 5081 5040 5032>,
			<6297 5512 5198 5080 5034 5024>,
			<6349 5541 5207 5075 5031 5023>,
			<6404 5571 5211 5072 5031 5023>,
			<6461 5601 5211 5073 5034 5026>,
			<6503 5621 5211 5073 5035 5028>,
			<6442 5590 5199 5066 5030 5023>,
			<6527 5636 5206 5069 5032 5024>,
			<6640 5704 5215 5065 5024 5015>,
			<6772 5810 5239 5071 5033 5025>,
			<6843 5883 5259 5078 5040 5032>,
			<6918 5966 5284 5088 5048 5044>,
			<7000 6073 5318 5099 5063 5058>,
			<7105 6204 5366 5111 5067 5057>,
			<7216 6346 5390 5101 5043 5033>,
			<7397 6558 5431 5095 5043 5034>,
			<7841 6888 5552 5109 5049 5040>,
			<9333 7230 5751 5139 5070 5058>,
			<9333 7230 5751 5139 5070 5058>,
			<9333 7230 5751 5139 5070 5058>;
	};

};
